# ATSAML21J18A register map
Vendor: Microchip Technology; Series: SAML21; File version: 0
CPU: CM0+ r0p0, selectable endian, no MPU, no FPU, 2 interrupt priority bits
Registers are 32-bit, read-write, reset 0x0 unless marked. A register's access mark holds for its fields unless they carry their own. Offsets are from the block's base; [hi:lo] are bit positions; lines under a group give offsets from that group; {n}, {i} and the like mark numbered series.

## PORT — Port Module
Base 0x40002800; register names take the prefix PORT_
Same registers: PORT_IOBUS 0x60000000 (register names take the prefix PORT_IOBUS_)
{0x0+0x80*i} GROUP[{i}] (i=0..1) group
  0x00 DIR — Data Direction
    [31:0] DIR — Port Data Direction
  0x04 DIRCLR — Data Direction Clear
    [31:0] DIRCLR — Port Data Direction Clear
  0x08 DIRSET — Data Direction Set
    [31:0] DIRSET — Port Data Direction Set
  0x0C DIRTGL — Data Direction Toggle
    [31:0] DIRTGL — Port Data Direction Toggle
  0x10 OUT — Data Output Value
    [31:0] OUT — Port Data Output Value
  0x14 OUTCLR — Data Output Value Clear
    [31:0] OUTCLR — Port Data Output Value Clear
  0x18 OUTSET — Data Output Value Set
    [31:0] OUTSET — Port Data Output Value Set
  0x1C OUTTGL — Data Output Value Toggle
    [31:0] OUTTGL — Port Data Output Value Toggle
  0x20 IN ro — Data Input Value
    [31:0] IN — Port Data Input Value
  0x24 CTRL — Control
    [31:0] SAMPLING — Input Sampling Mode
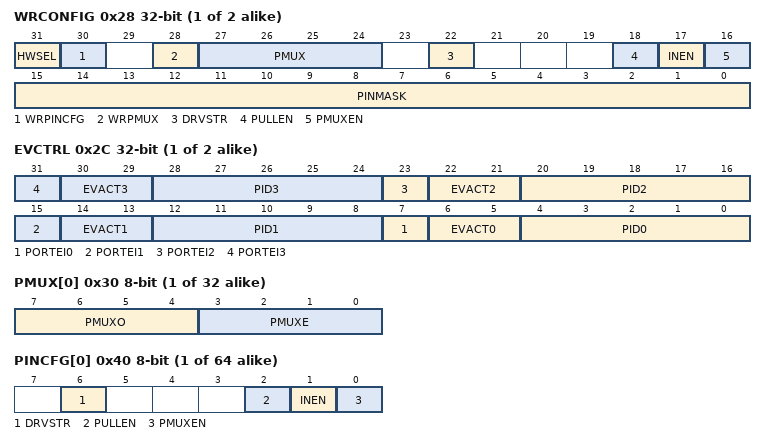
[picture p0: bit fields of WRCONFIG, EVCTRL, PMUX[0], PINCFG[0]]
  0x28 WRCONFIG wo — Write Configuration
    [31] HWSEL — Half-Word Select
    [30] WRPINCFG — Write PINCFG Registers
    [28] WRPMUX — Write PMUX Registers
    [27:24] PMUX — Peripheral Multiplexing Template
    [22] DRVSTR — Output Driver Strength Selection
    [18] PULLEN — Pull Enable
    [17] INEN — Input Enable
    [16] PMUXEN — Select Peripheral Multiplexer
    [15:0] PINMASK — Pin Mask for Multiple Pin Configuration
  0x2C EVCTRL — Event Input Control
    [8n+7] PORTEI{n} (n=0..3) — Port Event Enable Input {n}
    [8n+6:8n+5] EVACT{n} (n=0..3) — Port Event Action {n}
    [8n+4:8n] PID{n} (n=0..3) — Port Event Pin Identifier {n}
  {0x30+j} PMUX[{j}] (j=0..15) 8-bit — Peripheral Multiplexing n
    [7:4] PMUXO — Peripheral Multiplexing for Odd-Numbered Pin
    [3:0] PMUXE — Peripheral Multiplexing for Even-Numbered Pin
  {0x40+j} PINCFG[{j}] (j=0..31) 8-bit — Pin Configuration n
    [6] DRVSTR — Output Driver Strength Selection
    [2] PULLEN — Pull Enable
    [1] INEN — Input Enable
    [0] PMUXEN — Select Peripheral Multiplexer

## PTC — Peripheral Touch Controller
Base 0x43001400; register names take the prefix PTC_

## RSTC — Reset Controller
Base 0x40000800; register names take the prefix RSTC_
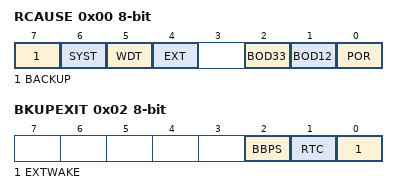
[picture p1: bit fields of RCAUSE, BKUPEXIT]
0x00 RCAUSE 8-bit ro — Reset Cause
  [7] BACKUP — Backup Reset
  [6] SYST — System Reset Request
  [5] WDT — Watchdog Reset
  [4] EXT — External Reset
  [2] BOD33 — Brown Out 33 Detector Reset
  [1] BOD12 — Brown Out 12 Detector Reset
  [0] POR — Power On Reset
0x02 BKUPEXIT 8-bit ro — Backup Exit Source
  [2] BBPS — Battery Backup Power Switch
  [1] RTC — Real Timer Counter Interrupt
  [0] EXTWAKE — External Wakeup
0x04 WKDBCONF 8-bit — Wakeup Debounce Configuration
  [4:0] WKDBCNT — Wakeup Debounce Counter
    0=OFF (No debouncing.Input pin is low or high level sensitive depending on its WKPOLx bit.); 1=2CK32 (Input pin shall be active for at least two 32kHz clock period.); 2=3CK32 (Input pin shall be active for at least three 32kHz clock period.); 3=32CK32 (Input pin shall be active for at least 32 32kHz clock period.); 4=512CK32 (Input pin shall be active for at least 512 32kHz clock period.); 5=4096CK32 (Input pin shall be active for at least 4096 32kHz clock period.); 6=32768CK32 (Input pin shall be active for at least 32768 32kHz clock period.)
0x08 WKPOL 16-bit — Wakeup Polarity
0x0C WKEN 16-bit — Wakeup Enable
0x10 WKCAUSE 16-bit — Wakeup Cause

## TRNG — True Random Generator
Base 0x42003800; register names take the prefix TRNG_
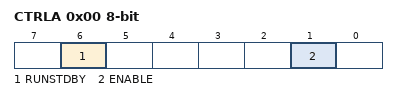
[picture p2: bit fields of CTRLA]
0x00 CTRLA 8-bit — Control A
  [6] RUNSTDBY — Run in Standby
  [1] ENABLE
0x04 EVCTRL 8-bit — Event Control
  [0] DATARDYEO — Data Ready Event Output
0x08 INTENCLR 8-bit — Interrupt Enable Clear
  [0] DATARDY — Data Ready Interrupt Enable
0x09 INTENSET 8-bit — Interrupt Enable Set
  [0] DATARDY — Data Ready Interrupt Enable
0x0A INTFLAG 8-bit — Interrupt Flag Status and Clear
  [0] DATARDY — Data Ready Interrupt Flag
0x20 DATA ro — Output Data

## Notices in the file
Copyright (c) 2017 Microchip Technology Inc.
SPDX-License-Identifier: Apache-2.0
Licensed under the Apache License, Version 2.0 (the "License");
you may not use this file except in compliance with the License.
You may obtain a copy of the License at
http://www.apache.org/licenses/LICENSE-2.0
Unless required by applicable law or agreed to in writing, software
distributed under the License is distributed on an "AS IS" BASIS,
WITHOUT WARRANTIES OR CONDITIONS OF ANY KIND, either express or implied.
See the License for the specific language governing permissions and
limitations under the License.
